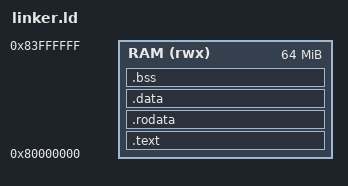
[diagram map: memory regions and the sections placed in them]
OUTPUT_ARCH(riscv)
ENTRY(_start)

MEMORY
{
    RAM (rwx) : ORIGIN = 0x80000000, LENGTH = 64M
}

SECTIONS
{
    .text : {
        *(.text.start)
        *(.text)
        *(.text.*)
    } > RAM

    .rodata : {
        *(.rodata)
        *(.rodata.*)
    } > RAM

    .data : {
        *(.data)
        *(.data.*)
    } > RAM

    .bss : {
        *(.bss)
        *(.bss.*)
    } > RAM

    . = ALIGN(16);
    . = . + 0x4000;
    _stack_top = .;
}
